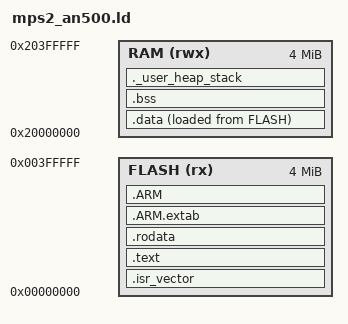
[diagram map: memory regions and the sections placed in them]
/*
*********************************************************************************************************
*                       Linker script - QEMU mps2-an500 (ARM Cortex-M7)
*
* Memory map taken authoritatively from QEMU 'info mtree' for -M mps2-an500:
*   ssram1   @ 0x00000000  4 MiB   -> code + vectors  (CPU reads SP/PC from here at reset)
*   ssram2&3 @ 0x20000000  4 MiB   -> data + bss + heap + stack
*********************************************************************************************************
*/

ENTRY(Reset_Handler)

MEMORY
{
    FLASH (rx)  : ORIGIN = 0x00000000, LENGTH = 4M
    RAM   (rwx) : ORIGIN = 0x20000000, LENGTH = 4M
}

_estack = ORIGIN(RAM) + LENGTH(RAM);                /* top of RAM = 0x20400000                           */

_Min_Heap_Size  = 0x1000;
_Min_Stack_Size = 0x2000;

SECTIONS
{
    .isr_vector :
    {
        . = ALIGN(4);
        KEEP(*(.isr_vector))
        . = ALIGN(4);
    } > FLASH

    .text :
    {
        . = ALIGN(4);
        *(.text)
        *(.text*)
        *(.glue_7)
        *(.glue_7t)
        *(.eh_frame)
        KEEP(*(.init))
        KEEP(*(.fini))
        . = ALIGN(4);
        _etext = .;
    } > FLASH

    .rodata :
    {
        . = ALIGN(4);
        *(.rodata)
        *(.rodata*)
        . = ALIGN(4);
    } > FLASH

    .ARM.extab :
    {
        *(.ARM.extab* .gnu.linkonce.armextab.*)
    } > FLASH

    .ARM :
    {
        __exidx_start = .;
        *(.ARM.exidx*)
        __exidx_end = .;
    } > FLASH

    . = ALIGN(4);
    _sidata = LOADADDR(.data);

    .data :
    {
        . = ALIGN(4);
        _sdata = .;
        *(.data)
        *(.data*)
        . = ALIGN(4);
        _edata = .;
    } > RAM AT> FLASH

    .bss :
    {
        . = ALIGN(4);
        _sbss = .;
        __bss_start__ = _sbss;
        *(.bss)
        *(.bss*)
        *(COMMON)
        . = ALIGN(4);
        _ebss = .;
        __bss_end__ = _ebss;
    } > RAM

    ._user_heap_stack :
    {
        . = ALIGN(8);
        PROVIDE ( end = . );
        PROVIDE ( _end = . );
        . = . + _Min_Heap_Size;
        . = . + _Min_Stack_Size;
        . = ALIGN(8);
    } > RAM

    .ARM.attributes 0 : { *(.ARM.attributes) }
}
